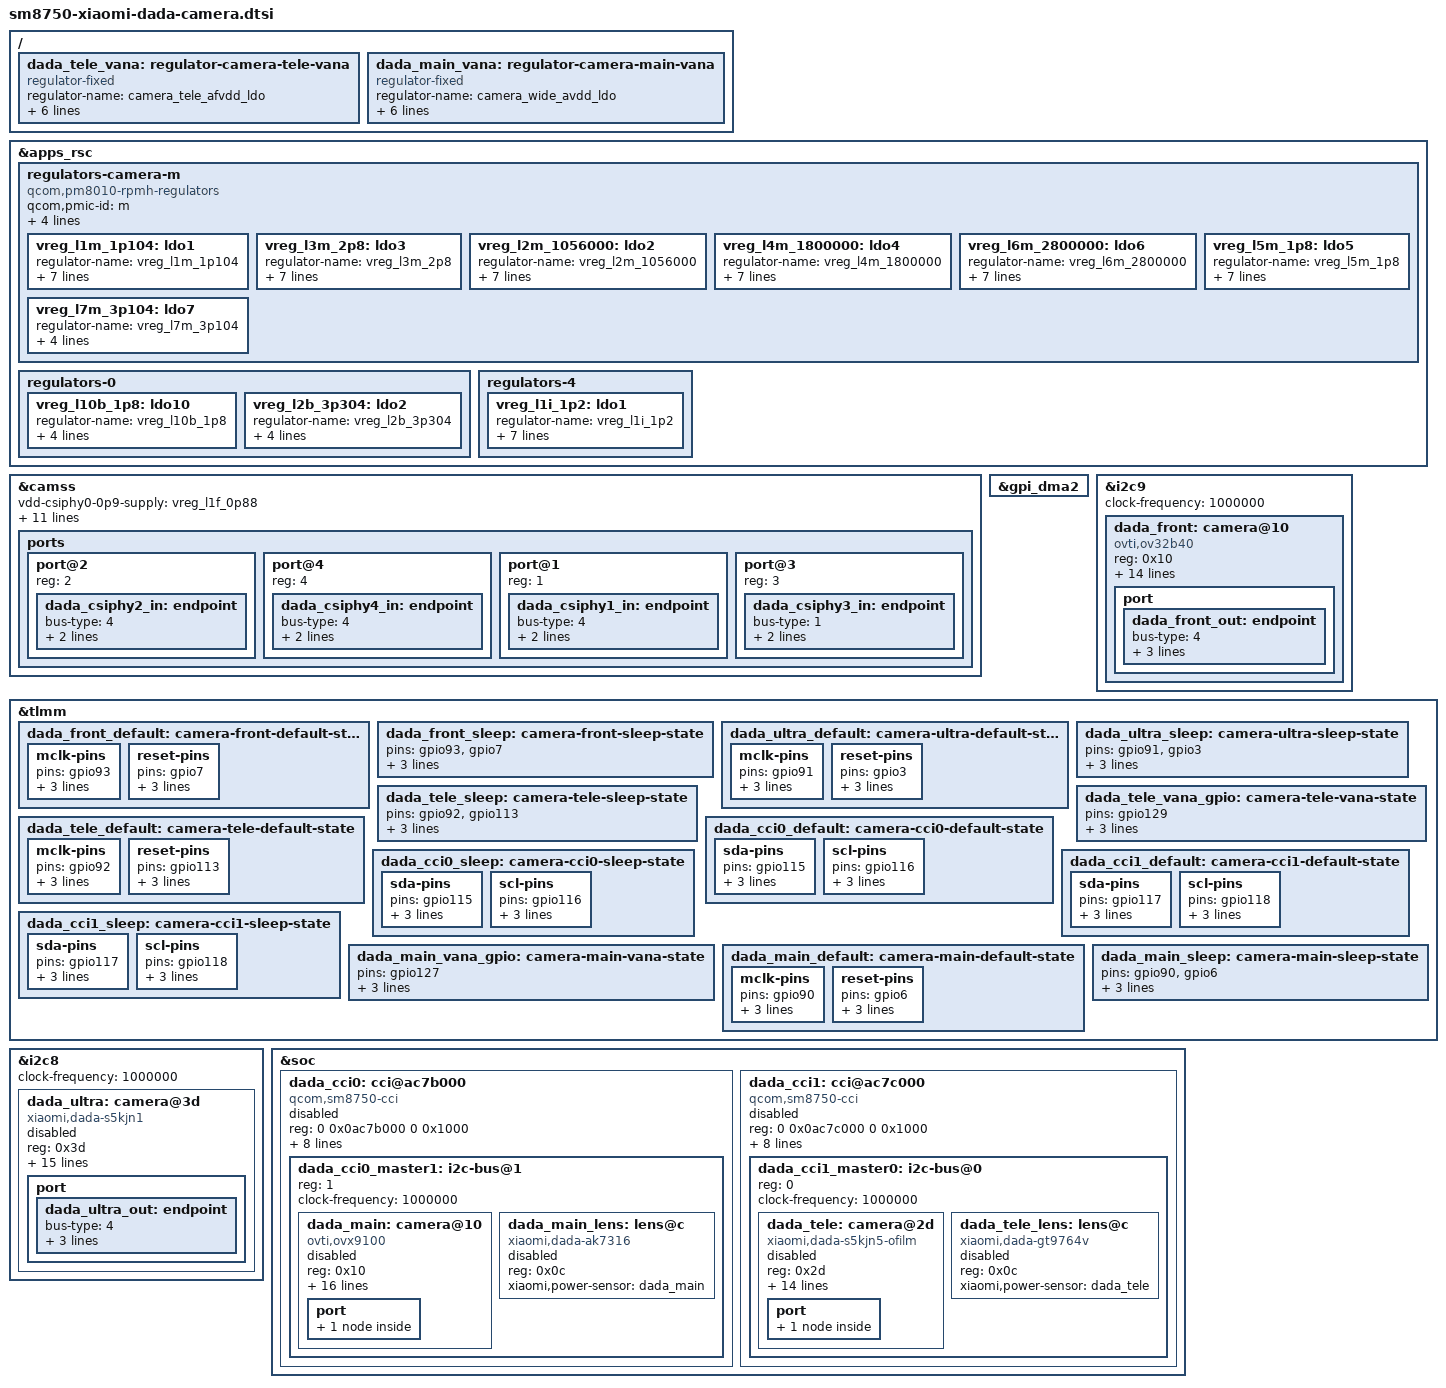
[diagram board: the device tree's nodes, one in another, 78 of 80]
// SPDX-License-Identifier: (GPL-2.0-only OR BSD-2-Clause)
/* Xiaomi dada camera sensor, lens and power configuration. */
#include <dt-bindings/gpio/gpio.h>
#include <dt-bindings/clock/qcom,sm8750-cambistmclkcc.h>
#include <dt-bindings/clock/qcom,sm8750-camcc.h>
#include <dt-bindings/regulator/qcom,rpmh-regulator.h>

&apps_rsc {
	regulators-camera-m {
		compatible = "qcom,pm8010-rpmh-regulators";
		qcom,pmic-id = "m";
		vdd-l1-l2-supply = <&vreg_s7i_1p2>;
		vdd-l3-l4-supply = <&vreg_bob2>;
		vdd-l5-supply = <&vreg_s3g_1p8>;
		vdd-l6-supply = <&vreg_bob2>;

		vreg_l1m_1p104: ldo1 {
			regulator-name = "vreg_l1m_1p104";
			regulator-min-microvolt = <1104000>;
			regulator-max-microvolt = <1104000>;
			regulator-initial-mode = <RPMH_REGULATOR_MODE_HPM>;
			regulator-allow-set-load;
			regulator-allowed-modes = <RPMH_REGULATOR_MODE_LPM
						   RPMH_REGULATOR_MODE_HPM>;
		};

		vreg_l3m_2p8: ldo3 {
			regulator-name = "vreg_l3m_2p8";
			regulator-min-microvolt = <2800000>;
			regulator-max-microvolt = <2800000>;
			regulator-initial-mode = <RPMH_REGULATOR_MODE_HPM>;
			regulator-allow-set-load;
			regulator-allowed-modes = <RPMH_REGULATOR_MODE_LPM
						   RPMH_REGULATOR_MODE_HPM>;
		};

		vreg_l2m_1056000: ldo2 {
			regulator-name = "vreg_l2m_1056000";
			regulator-min-microvolt = <1056000>;
			regulator-max-microvolt = <1056000>;
			regulator-initial-mode = <RPMH_REGULATOR_MODE_HPM>;
			regulator-allow-set-load;
			regulator-allowed-modes = <RPMH_REGULATOR_MODE_LPM
						   RPMH_REGULATOR_MODE_HPM>;
		};

		vreg_l4m_1800000: ldo4 {
			regulator-name = "vreg_l4m_1800000";
			regulator-min-microvolt = <1800000>;
			regulator-max-microvolt = <1800000>;
			regulator-initial-mode = <RPMH_REGULATOR_MODE_HPM>;
			regulator-allow-set-load;
			regulator-allowed-modes = <RPMH_REGULATOR_MODE_LPM
						   RPMH_REGULATOR_MODE_HPM>;
		};

		vreg_l6m_2800000: ldo6 {
			regulator-name = "vreg_l6m_2800000";
			regulator-min-microvolt = <2800000>;
			regulator-max-microvolt = <2800000>;
			regulator-initial-mode = <RPMH_REGULATOR_MODE_HPM>;
			regulator-allow-set-load;
			regulator-allowed-modes = <RPMH_REGULATOR_MODE_LPM
						   RPMH_REGULATOR_MODE_HPM>;
		};

		vreg_l5m_1p8: ldo5 {
			regulator-name = "vreg_l5m_1p8";
			regulator-min-microvolt = <1800000>;
			regulator-max-microvolt = <1800000>;
			regulator-initial-mode = <RPMH_REGULATOR_MODE_HPM>;
			regulator-allow-set-load;
			regulator-allowed-modes = <RPMH_REGULATOR_MODE_LPM
						   RPMH_REGULATOR_MODE_HPM>;
		};
	};
};

&camss {
	/* Stock CSIPHY0/1/3/5: L1F; CSIPHY2/4: L3I. All use L3G. */
	vdd-csiphy0-0p9-supply = <&vreg_l1f_0p88>;
	vdd-csiphy1-0p9-supply = <&vreg_l1f_0p88>;
	vdd-csiphy2-0p9-supply = <&vreg_l3i_0p88>;
	vdd-csiphy3-0p9-supply = <&vreg_l1f_0p88>;
	vdd-csiphy4-0p9-supply = <&vreg_l3i_0p88>;
	vdd-csiphy5-0p9-supply = <&vreg_l1f_0p88>;
	vdd-csiphy0-1p2-supply = <&vreg_l3g_1p2>;
	vdd-csiphy1-1p2-supply = <&vreg_l3g_1p2>;
	vdd-csiphy2-1p2-supply = <&vreg_l3g_1p2>;
	vdd-csiphy3-1p2-supply = <&vreg_l3g_1p2>;
	vdd-csiphy4-1p2-supply = <&vreg_l3g_1p2>;
	vdd-csiphy5-1p2-supply = <&vreg_l3g_1p2>;
	/* Rear sensors stay disabled until individually validated. */
	status = "okay";

	ports {
		port@2 {
			reg = <2>;
			dada_csiphy2_in: endpoint {
				bus-type = <4>;
				data-lanes = <0 1 2 3>;
				remote-endpoint = <&dada_ultra_out>;
			};
		};

		port@4 {
			reg = <4>;
			dada_csiphy4_in: endpoint {
				bus-type = <4>;
				/* Stock laneAssign=0x3210; D-PHY clock lane is fixed. */
				data-lanes = <0 1 2 3>;
				remote-endpoint = <&dada_front_out>;
			};
		};
	};
};

/* I2C9 uses GPI DMA; the provider must be enabled with the sensor bus. */
&gpi_dma2 {
	status = "okay";
};

&i2c9 {
	clock-frequency = <1000000>;
	status = "okay";

	dada_front: camera@10 {
		compatible = "ovti,ov32b40";
		reg = <0x10>;
		power-domains = <&camcc CAM_CC_TITAN_TOP_GDSC>;
		clocks = <&cambistmclkcc CAM_BIST_MCLK_CC_MCLK4_CLK>;
		assigned-clocks = <&cambistmclkcc CAM_BIST_MCLK_CC_MCLK4_CLK>;
		assigned-clock-rates = <19200000>;
		avdd-supply = <&vreg_l3m_2p8>;
		dovdd-supply = <&vreg_l5m_1p8>;
		dvdd-supply = <&vreg_l1m_1p104>;
		reset-gpios = <&tlmm 7 GPIO_ACTIVE_LOW>;
		pinctrl-names = "default", "sleep";
		pinctrl-0 = <&dada_front_default>;
		pinctrl-1 = <&dada_front_sleep>;
		orientation = <0>;
		rotation = <270>;

		port {
			dada_front_out: endpoint {
				bus-type = <4>;
				data-lanes = <1 2 3 4>;
				link-frequencies = /bits/ 64 <842400000>;
				remote-endpoint = <&dada_csiphy4_in>;
			};
		};
	};
};

&tlmm {
	dada_front_default: camera-front-default-state {
		mclk-pins {
			pins = "gpio93";
			function = "cam_aon_mclk4";
			drive-strength = <2>;
			bias-disable;
		};
		reset-pins {
			pins = "gpio7";
			function = "gpio";
			drive-strength = <2>;
			bias-disable;
		};
	};

	dada_front_sleep: camera-front-sleep-state {
		pins = "gpio93", "gpio7";
		function = "gpio";
		drive-strength = <2>;
		bias-pull-down;
	};
};

/* Stock QUP I2C8, slave write address 0x7a -> Linux address 0x3d. */
&i2c8 {
	clock-frequency = <1000000>;
	status = "okay";

	dada_ultra: camera@3d {
		compatible = "xiaomi,dada-s5kjn1";
		reg = <0x3d>;
		status = "disabled";
		power-domains = <&camcc CAM_CC_TITAN_TOP_GDSC>;
		clocks = <&cambistmclkcc CAM_BIST_MCLK_CC_MCLK2_CLK>;
		assigned-clocks = <&cambistmclkcc CAM_BIST_MCLK_CC_MCLK2_CLK>;
		assigned-clock-rates = <19200000>;
		vdda-supply = <&vreg_l6m_2800000>;
		vddd-supply = <&vreg_l2m_1056000>;
		vddio-supply = <&vreg_l4m_1800000>;
		vboost-supply = <&vreg_bob2>;
		reset-gpios = <&tlmm 3 GPIO_ACTIVE_LOW>;
		pinctrl-names = "default", "sleep";
		pinctrl-0 = <&dada_ultra_default>;
		pinctrl-1 = <&dada_ultra_sleep>;
		orientation = <1>;
		rotation = <90>;

		port {
			dada_ultra_out: endpoint {
				bus-type = <4>;
				data-lanes = <1 2 3 4>;
				/* 19.2 MHz / 3 * 154; D-PHY link clock. */
				link-frequencies = /bits/ 64 <985600000>;
				remote-endpoint = <&dada_csiphy2_in>;
			};
		};
	};
};

&tlmm {
	dada_ultra_default: camera-ultra-default-state {
		mclk-pins {
			pins = "gpio91";
			function = "cam_aon_mclk2";
			drive-strength = <2>;
			bias-disable;
		};
		reset-pins {
			pins = "gpio3";
			function = "gpio";
			drive-strength = <2>;
			bias-disable;
		};
	};

	dada_ultra_sleep: camera-ultra-sleep-state {
		pins = "gpio91", "gpio3";
		function = "gpio";
		drive-strength = <2>;
		bias-pull-down;
	};
};

/ {
	dada_tele_vana: regulator-camera-tele-vana {
		compatible = "regulator-fixed";
		regulator-name = "camera_tele_afvdd_ldo";
		regulator-min-microvolt = <2200000>;
		regulator-max-microvolt = <2200000>;
		gpio = <&tlmm 129 GPIO_ACTIVE_HIGH>;
		enable-active-high;
		regulator-enable-ramp-delay = <100>;
		pinctrl-names = "default";
		pinctrl-0 = <&dada_tele_vana_gpio>;
		/* Stock DT has no vin-supply: its physical input is unknown. */
	};
};

&apps_rsc {
	regulators-0 {
		vreg_l10b_1p8: ldo10 {
			regulator-name = "vreg_l10b_1p8";
			regulator-min-microvolt = <1800000>;
			regulator-max-microvolt = <1800000>;
			regulator-initial-mode = <RPMH_REGULATOR_MODE_HPM>;
		};
	};

	regulators-camera-m {
		/* Stock L7M has no physical parent supply property. */
		vreg_l7m_3p104: ldo7 {
			regulator-name = "vreg_l7m_3p104";
			regulator-min-microvolt = <3104000>;
			regulator-max-microvolt = <3104000>;
			regulator-initial-mode = <RPMH_REGULATOR_MODE_HPM>;
		};
	};
};


&camss {
	ports {
		port@1 {
			reg = <1>;
			dada_csiphy1_in: endpoint {
				bus-type = <4>;
				data-lanes = <0 1 2 3>;
				remote-endpoint = <&dada_tele_out>;
			};
		};
	};
};

&tlmm {
	dada_tele_vana_gpio: camera-tele-vana-state {
		pins = "gpio129";
		function = "gpio";
		drive-strength = <2>;
		bias-disable;
	};

	dada_tele_default: camera-tele-default-state {
		mclk-pins {
			pins = "gpio92";
			function = "cam_mclk";
			drive-strength = <2>;
			bias-disable;
		};
		reset-pins {
			pins = "gpio113";
			function = "gpio";
			drive-strength = <2>;
			bias-disable;
		};
	};

	dada_tele_sleep: camera-tele-sleep-state {
		pins = "gpio92", "gpio113";
		function = "gpio";
		drive-strength = <2>;
		bias-pull-down;
	};
};

&soc {

	dada_cci0: cci@ac7b000 {
		compatible = "qcom,sm8750-cci", "qcom,msm8996-cci";
		reg = <0 0x0ac7b000 0 0x1000>;
		interrupts = <GIC_SPI 426 IRQ_TYPE_EDGE_RISING>;
		power-domains = <&camcc CAM_CC_TITAN_TOP_GDSC>;
		clocks = <&camcc CAM_CC_CAM_TOP_AHB_CLK>,
			 <&camcc CAM_CC_CCI_0_CLK>;
		clock-names = "ahb", "cci";
		assigned-clocks = <&camcc CAM_CC_CCI_0_CLK>;
		assigned-clock-rates = <37500000>;
		pinctrl-names = "default", "sleep";
		pinctrl-0 = <&dada_cci0_default>;
		pinctrl-1 = <&dada_cci0_sleep>;
		status = "disabled";
		#address-cells = <1>;
		#size-cells = <0>;

		dada_cci0_master1: i2c-bus@1 {
			reg = <1>;
			clock-frequency = <1000000>;
			#address-cells = <1>;
			#size-cells = <0>;
		};
	};

	dada_cci1: cci@ac7c000 {
		compatible = "qcom,sm8750-cci", "qcom,msm8996-cci";
		reg = <0 0x0ac7c000 0 0x1000>;
		interrupts = <GIC_SPI 427 IRQ_TYPE_EDGE_RISING>;
		power-domains = <&camcc CAM_CC_TITAN_TOP_GDSC>;
		clocks = <&camcc CAM_CC_CAM_TOP_AHB_CLK>,
			 <&camcc CAM_CC_CCI_1_CLK>;
		clock-names = "ahb", "cci";
		assigned-clocks = <&camcc CAM_CC_CCI_1_CLK>;
		assigned-clock-rates = <37500000>;
		pinctrl-names = "default", "sleep";
		pinctrl-0 = <&dada_cci1_default>;
		pinctrl-1 = <&dada_cci1_sleep>;
		status = "disabled";
		#address-cells = <1>;
		#size-cells = <0>;

		dada_cci1_master0: i2c-bus@0 {
			reg = <0>;
			clock-frequency = <1000000>;
			#address-cells = <1>;
			#size-cells = <0>;
		};
	};
};

&tlmm {
	dada_cci0_default: camera-cci0-default-state {
		sda-pins {
			pins = "gpio115";
			function = "cci_i2c_sda";
			drive-strength = <2>;
			bias-disable;
		};
		scl-pins {
			pins = "gpio116";
			function = "cci_i2c_scl";
			drive-strength = <2>;
			bias-disable;
		};
	};

	dada_cci0_sleep: camera-cci0-sleep-state {
		sda-pins {
			pins = "gpio115";
			function = "cci_i2c_sda";
			drive-strength = <2>;
			bias-pull-down;
		};
		scl-pins {
			pins = "gpio116";
			function = "cci_i2c_scl";
			drive-strength = <2>;
			bias-pull-down;
		};
	};

	dada_cci1_default: camera-cci1-default-state {
		sda-pins {
			pins = "gpio117";
			function = "cci_i2c_sda";
			drive-strength = <2>;
			bias-disable;
		};
		scl-pins {
			pins = "gpio118";
			function = "cci_i2c_scl";
			drive-strength = <2>;
			bias-disable;
		};
	};

	dada_cci1_sleep: camera-cci1-sleep-state {
		sda-pins {
			pins = "gpio117";
			function = "cci_i2c_sda";
			drive-strength = <2>;
			bias-pull-down;
		};
		scl-pins {
			pins = "gpio118";
			function = "cci_i2c_scl";
			drive-strength = <2>;
			bias-pull-down;
		};
	};

};

&dada_cci1_master0 {
	#address-cells = <1>;
	#size-cells = <0>;
	dada_tele: camera@2d {
		compatible = "xiaomi,dada-s5kjn5-ofilm";
		/* Alternative: xiaomi,dada-s5kjn5-sunny, two mode writes differ. */
		reg = <0x2d>;
		status = "disabled";
		power-domains = <&camcc CAM_CC_TITAN_TOP_GDSC>;
		clocks = <&cambistmclkcc CAM_BIST_MCLK_CC_MCLK3_CLK>;
		assigned-clocks = <&cambistmclkcc CAM_BIST_MCLK_CC_MCLK3_CLK>;
		assigned-clock-rates = <19200000>;
		bob-supply = <&vreg_bob2>;
		vddio-supply = <&vreg_l10b_1p8>;
		afvdd-supply = <&vreg_l7m_3p104>;
		vdda-supply = <&dada_tele_vana>;
		vddd-supply = <&vreg_l11b_1p0>;
		reset-gpios = <&tlmm 113 GPIO_ACTIVE_LOW>;
		pinctrl-names = "default", "sleep";
		pinctrl-0 = <&dada_tele_default>;
		pinctrl-1 = <&dada_tele_sleep>;

		port {
			dada_tele_out: endpoint {
				bus-type = <4>;
				data-lanes = <1 2 3 4>;
				link-frequencies = /bits/ 64 <1248000000>;
				remote-endpoint = <&dada_csiphy1_in>;
			};
		};
	};
};

/ {
	dada_main_vana: regulator-camera-main-vana {
		compatible = "regulator-fixed";
		regulator-name = "camera_wide_avdd_ldo";
		regulator-min-microvolt = <2900000>;
		regulator-max-microvolt = <2900000>;
		gpio = <&tlmm 127 GPIO_ACTIVE_HIGH>;
		enable-active-high;
		regulator-enable-ramp-delay = <100>;
		pinctrl-names = "default";
		pinctrl-0 = <&dada_main_vana_gpio>;
	};
};

&apps_rsc {
	regulators-0 {
		vreg_l2b_3p304: ldo2 {
			regulator-name = "vreg_l2b_3p304";
			regulator-min-microvolt = <3304000>;
			regulator-max-microvolt = <3304000>;
			regulator-initial-mode = <RPMH_REGULATOR_MODE_HPM>;
		};
	};
};

/* Stock cam-sensor0 cam_vdig phandle 0x411 resolves to ldoi1. */
&apps_rsc {
	regulators-4 {
		vreg_l1i_1p2: ldo1 {
			regulator-name = "vreg_l1i_1p2";
			regulator-min-microvolt = <1200000>;
			regulator-max-microvolt = <1200000>;
			regulator-initial-mode = <RPMH_REGULATOR_MODE_HPM>;
			regulator-allow-set-load;
			regulator-allowed-modes = <RPMH_REGULATOR_MODE_LPM
						   RPMH_REGULATOR_MODE_HPM>;
		};
	};
};

&dada_cci0_master1 {
	dada_main: camera@10 {
		compatible = "ovti,ovx9100";
		reg = <0x10>;
		status = "disabled";
		power-domains = <&camcc CAM_CC_TITAN_TOP_GDSC>;
		clocks = <&cambistmclkcc CAM_BIST_MCLK_CC_MCLK1_CLK>;
		assigned-clocks = <&cambistmclkcc CAM_BIST_MCLK_CC_MCLK1_CLK>;
		assigned-clock-rates = <19200000>;
		bob-supply = <&vreg_bob2>;
		vaf-supply = <&vreg_l2b_3p304>;
		avdd-supply = <&dada_main_vana>;
		dovdd-supply = <&vreg_l10b_1p8>;
		dvdd-supply = <&vreg_l1i_1p2>;
		reset-gpios = <&tlmm 6 GPIO_ACTIVE_LOW>;
		pinctrl-names = "default", "sleep";
		pinctrl-0 = <&dada_main_default>;
		pinctrl-1 = <&dada_main_sleep>;
		orientation = <1>;
		rotation = <90>;
		port {
			dada_main_out: endpoint {
				bus-type = <1>;
				data-lanes = <0 1 2>;
				remote-endpoint = <&dada_csiphy3_in>;
			};
		};
	};
};

&camss {
	ports {
		port@3 {
			reg = <3>;
			dada_csiphy3_in: endpoint {
				bus-type = <1>;
				data-lanes = <0 1 2>;
				remote-endpoint = <&dada_main_out>;
			};
		};
	};
};

&tlmm {
	dada_main_vana_gpio: camera-main-vana-state {
		pins = "gpio127";
		function = "gpio";
		drive-strength = <2>;
		bias-disable;
	};

	dada_main_default: camera-main-default-state {
		mclk-pins {
			pins = "gpio90";
			function = "cam_mclk";
			drive-strength = <2>;
			bias-disable;
		};
		reset-pins {
			pins = "gpio6";
			function = "gpio";
			drive-strength = <2>;
			bias-disable;
		};
	};

	dada_main_sleep: camera-main-sleep-state {
		pins = "gpio90", "gpio6";
		function = "gpio";
		drive-strength = <2>;
		bias-pull-down;
	};
};

/* Experimental lenses stay disabled outside dedicated AF test images. */
&dada_cci0_master1 {
	dada_main_lens: lens@c {
		compatible = "xiaomi,dada-ak7316";
		reg = <0x0c>;
		xiaomi,power-sensor = <&dada_main>;
		status = "disabled";
	};
};

&dada_cci1_master0 {
	dada_tele_lens: lens@c {
		compatible = "xiaomi,dada-gt9764v";
		reg = <0x0c>;
		xiaomi,power-sensor = <&dada_tele>;
		status = "disabled";
	};
};
